# R7FA6M1AD register map
Vendor: Renesas; Series: RA6; File version: 1.2
CPU: CM4 r0p1, little endian, MPU, FPU, VTOR, 4 interrupt priority bits
Registers are 8-bit, read-write, reset 0x0 unless marked. A register's access mark holds for its fields unless they carry their own. Offsets are from the block's base; [hi:lo] are bit positions; {n}, {i} and the like mark numbered series.

## IRDA — Infrared Data Association
Base 0x40070F00
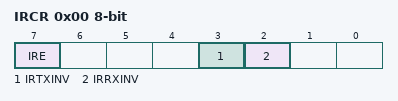
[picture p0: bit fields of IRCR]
0x00 IRCR — IrDA Control Register
  [7] IRE — IrDA Enable
  [3] IRTXINV — IRTXD Polarity Switching
  [2] IRRXINV — IRRXD Polarity Switching

## SRCRAM — Sampling Rate Converter RAM
Base 0x40048000
{0x0+4i} SRCFCTR[{i}] (i=0..5551) 32-bit (reset mask 0xFFC00000) — Filter Coefficient Table [{i}]
  [21:0] SRCFCOE — Stores a filter coefficient value.

## SRC — Sampling Rate Converter
Base 0x4004DFF0
0x00 SRCID 32-bit wo — Input Data Register
  [31:0] SRCID — SRCID is a 32-bit writ,only register that is used to input the data before sampling rate conversion. All the bits are read as 0.
0x04 SRCOD 32-bit ro — Output Data Register
  [31:0] SRCOD — SRCOD is a 32-bit read,only register used to output the data after sampling rate conversion. The data in the 16-stage output data FIFO is read through SRCOD. When the number of data in the output data FIFO is zero after the start of conversion, the value previously read is read again.
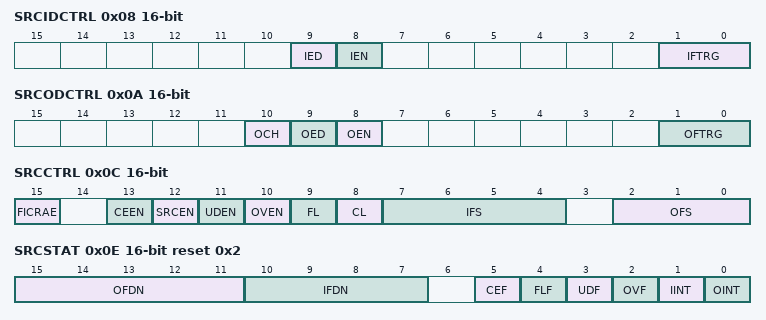
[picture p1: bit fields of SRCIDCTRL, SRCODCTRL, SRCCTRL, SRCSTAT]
0x08 SRCIDCTRL 16-bit — Input Data Control Register
  [9] IED — Input Data Endian
  [8] IEN — Input FIFO Empty Interrupt Enable
  [1:0] IFTRG — Input FIFO Data Triggering Number
0x0A SRCODCTRL 16-bit — Output Data Control Register
  [10] OCH — Output Data Channel Exchange
  [9] OED — Output Data Endian
  [8] OEN — Output Data FIFO Full Interrupt Enable
  [1:0] OFTRG — Output FIFO Data Trigger Number
0x0C SRCCTRL 16-bit — Control Register
  [15] FICRAE — Filter Coefficient Table Access Enable
  [13] CEEN — Conversion End Interrupt Enable
  [12] SRCEN — Module Enable
  [11] UDEN — Output Data FIFO Underflow Interrupt Enable
  [10] OVEN — Output Data FIFO Overwrite Interrupt Enable
  [9] FL wo — Internal Work Memory Flush
  [8] CL wo — Internal Work Memory Clear
  [7:4] IFS — Input Sampling Rate
  [2:0] OFS — Output Sampling Rate
0x0E SRCSTAT 16-bit reset 0x2 — Status Register
  [15:11] OFDN ro — Output FIFO Data Count
  [10:7] IFDN ro — Input FIFO Data Count
  [5] CEF write-0-clears read-modifies — Conversion End Flag
  [4] FLF ro — Flush Processing Status Flag
  [3] UDF write-0-clears read-modifies — Output FIFO Underflow Interrupt Request Flag
  [2] OVF write-0-clears read-modifies — Output Data FIFO Overwrite Interrupt Request Flag
  [1] IINT write-0-clears read-modifies — Input Data FIFO Empty Interrupt Request Flag
  [0] OINT write-0-clears read-modifies — Output Data FIFO Full Interrupt Request Flag

## DBG — Debug Function
Base 0x4001B000
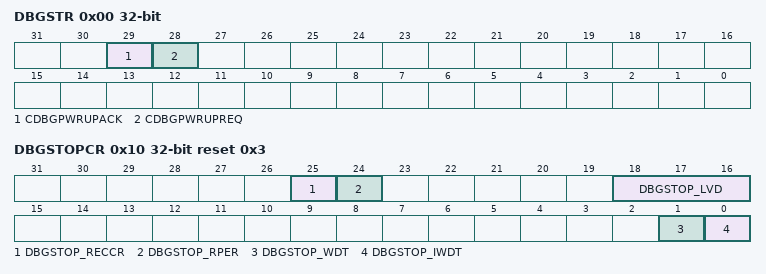
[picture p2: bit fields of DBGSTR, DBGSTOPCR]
0x00 DBGSTR 32-bit ro — Debug Status Register
  [29] CDBGPWRUPACK — Debug power,up acknowledge
  [28] CDBGPWRUPREQ — Debug power,up request
0x10 DBGSTOPCR 32-bit reset 0x3 — Debug Stop Control Register
  [25] DBGSTOP_RECCR — Mask bit for RAM ECC error reset/interrupt
  [24] DBGSTOP_RPER — Mask bit for RAM parity error reset/interrupt
  [18:16] DBGSTOP_LVD — b18: Mask bit for LVD2 reset/interrupt (0:enable / 1:Mask)b17: Mask bit for LVD1 reset/interrupt (0:enable / 1:Mask)b16: Mask bit for LVD0 reset (0:enable / 1:Mask)
  [1] DBGSTOP_WDT — Mask bit for WDT reset/interrupt
  [0] DBGSTOP_IWDT — Mask bit for IWDT reset/interrupt
0x20 TRACECTR 32-bit — Trace Control Register
  [31] ENETBFULL — Enable bit for halt request by ETB full

## DMAC0 — Direct memory access controller 0
Base 0x40005000
Same registers: DMAC1 0x40005040, DMAC2 0x40005080, DMAC3 0x400050C0, DMAC4 0x40005100, DMAC5 0x40005140, DMAC6 0x40005180, DMAC7 0x400051C0
0x00 DMSAR 32-bit — DMA Source Address Register
  [31:0] DMSAR — Specifies the transfer source start address.
0x04 DMDAR 32-bit — DMA Destination Address Register
  [31:0] DMDAR — Specifies the transfer destination start address.
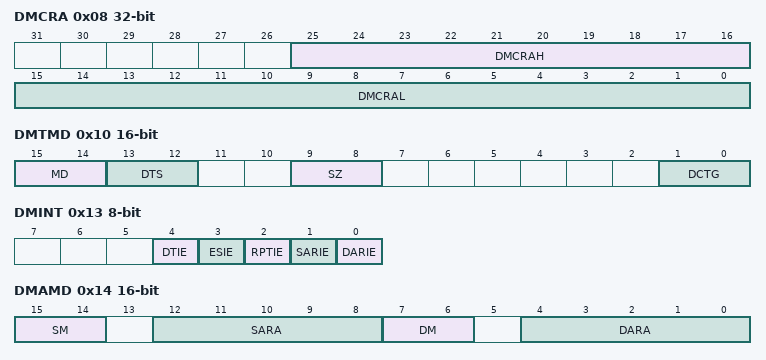
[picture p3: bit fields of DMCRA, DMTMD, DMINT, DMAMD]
0x08 DMCRA 32-bit — DMA Transfer Count Register
  [25:16] DMCRAH — Upper bits of transfer count
  [15:0] DMCRAL — Lower bits of transfer count
0x0C DMCRB 16-bit — DMA Block Transfer Count Register
  [15:0] DMCRB — Specifies the number of block transfer operations or repeat transfer operations.
0x10 DMTMD 16-bit — DMA Transfer Mode Register
  [15:14] MD — Transfer Mode Select
  [13:12] DTS — Repeat Area Select
  [9:8] SZ — Transfer Data Size Select
  [1:0] DCTG — Transfer Request Source Select
0x13 DMINT — DMA Interrupt Setting Register
  [4] DTIE — Transfer End Interrupt Enable
  [3] ESIE — Transfer Escape End Interrupt Enable
  [2] RPTIE — Repeat Size End Interrupt Enable
  [1] SARIE — Source Address Extended Repeat Area Overflow Interrupt Enable
  [0] DARIE — Destination Address Extended Repeat Area Overflow Interrupt Enable
0x14 DMAMD 16-bit — DMA Address Mode Register
  [15:14] SM — Source Address Update Mode
  [12:8] SARA — Source Address Extended Repeat Area Specifies the extended repeat area on the source address. For details on the settings.
  [7:6] DM — Destination Address Update Mode
  [4:0] DARA — Destination Address Extended Repeat Area Specifies the extended repeat area on the destination address. For details on the settings.
0x18 DMOFR 32-bit — DMA Offset Register
  [31:0] DMOFR — Specifies the offset when offset addition is selected as the address update mode for transfer source or destination.
0x1C DMCNT — DMA Transfer Enable Register
  [0] DTE read-modifies — DMA Transfer Enable
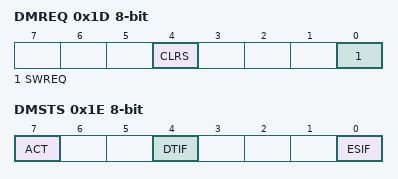
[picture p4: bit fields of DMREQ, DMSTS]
0x1D DMREQ — DMA Software Start Register
  [4] CLRS — DMA Software Start Bit Auto Clear Select
  [0] SWREQ read-modifies — DMA Software Start
0x1E DMSTS — DMAC Module Activation Register
  [7] ACT ro — DMA Active Flag
  [4] DTIF write-0-clears read-modifies — Transfer End Interrupt Flag
  [0] ESIF write-0-clears read-modifies — Transfer Escape End Interrupt Flag
